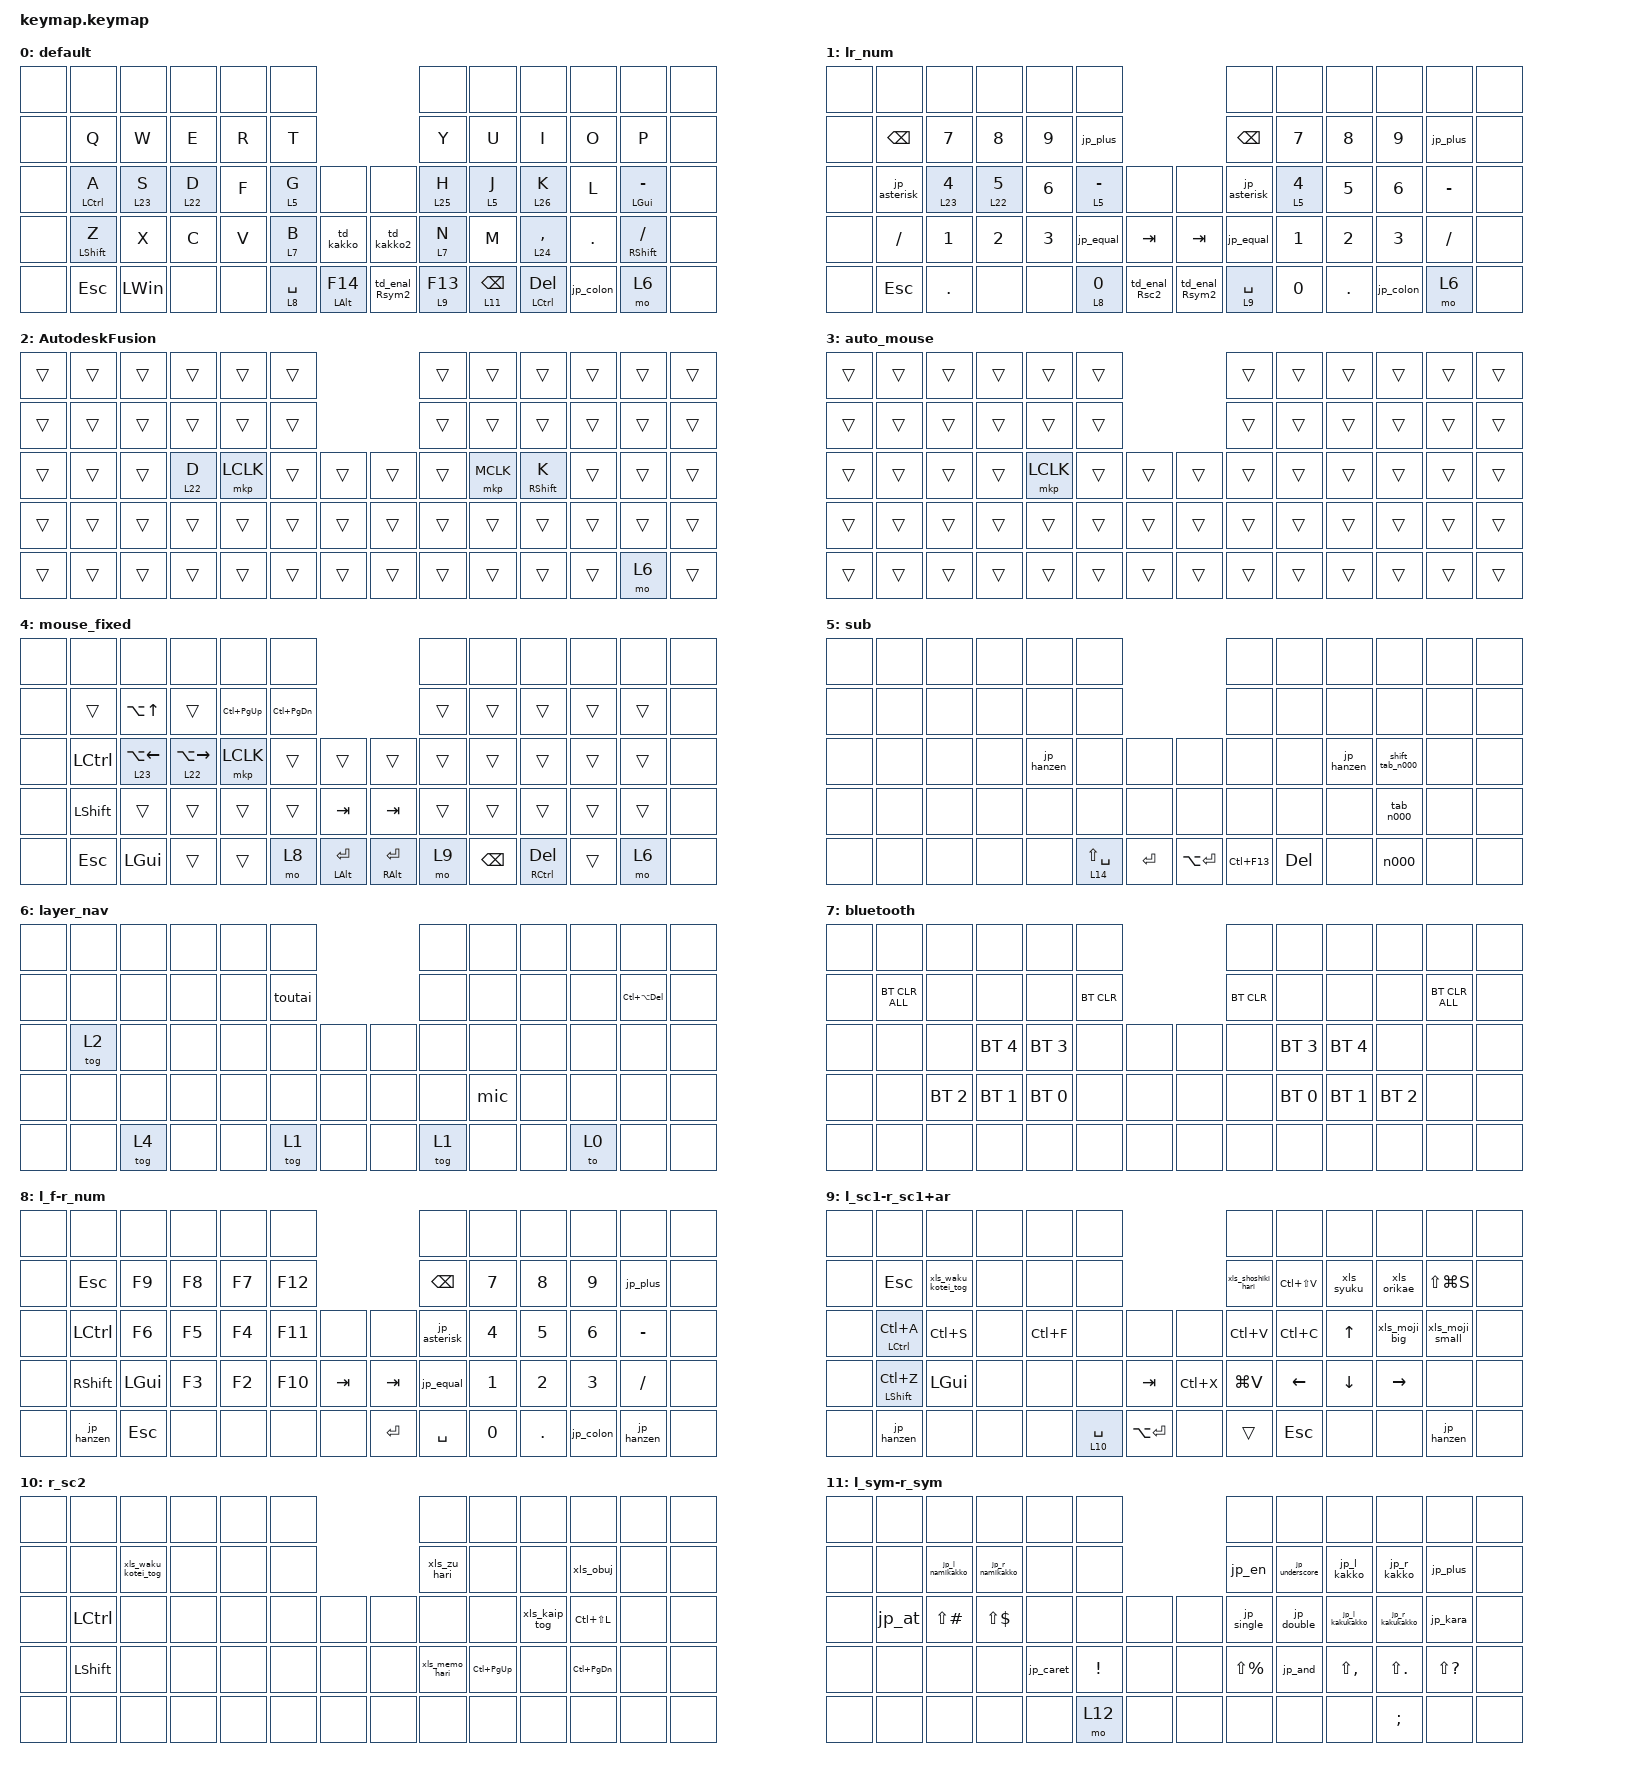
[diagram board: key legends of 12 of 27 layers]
/* 追記分（Input Processorsでレイヤー別動作やスクロール変換を使うため） */

#include <input/processors.dtsi>
#include <zephyr/dt-bindings/input/input-event-codes.h>
#include <dt-bindings/zmk/input_transform.h>
#include <dt-bindings/zmk/modifiers.h>
#include <behaviors.dtsi>
#include <dt-bindings/zmk/bt.h>
#include <dt-bindings/zmk/keys.h>
#include <dt-bindings/zmk/pointing.h>

/* HID usage(16進) をそのまま keycode 値として扱う（dtc が確実に数値として読める形） */

#define JP_KC_0x89  (0x89)  /* ¥ 系 */
#define JP_KC_0x87  (0x87)  /* _ 用 */

/* タップダンス用：行きたいレイヤー番号 */

#define LAYER_Rsc2 8
#define LAYER_LsRs 9
#define LAYER_Rsym2 10

/* ================== ここからDevicetreeオーバレイ本体 ================== */

/ {
    /* ===============================
     * トラックボール用 Input Processor 定義
     *  - my_vert_scroll   : Y → 縦スクロール
     *  - my_horiz_scroll  : X → 横スクロール
     *  - lock_cursor_x    : カーソルdXのみ 0倍（縦スクロール中に左右移動させない）
     *  - lock_cursor_y    : カーソルYのみ 0倍（横スクロール中に上下移動させない）
     * =============================== */

    input_processors {
        /* --- 縦スクロール専用 Code Mapper（Y → WHEEL） --- */

        my_vert_scroll: my_vert_scroll {
            compatible = "zmk,input-processor-code-mapper";
            #input-processor-cells = <0>;
            type = <INPUT_EV_REL>;
            map = <INPUT_REL_Y INPUT_REL_WHEEL>;
        };

        /* --- 横スクロール専用 Code Mapper（X → HWHEEL） --- */

        my_horiz_scroll: my_horiz_scroll {
            compatible = "zmk,input-processor-code-mapper";
            #input-processor-cells = <0>;
            type = <INPUT_EV_REL>;
            map = <INPUT_REL_X INPUT_REL_HWHEEL>;
        };

        /* --- カーソル X だけスケール 0倍にする（縦スクロール時に使用） --- */

        lock_cursor_x: lock_cursor_x {
            compatible = "zmk,input-processor-scaler";
            #input-processor-cells = <2>;   /* パラメータ 2つ（分子, 分母） */
            type = <INPUT_EV_REL>;

            /* X 方向の相対移動だけを対象 */

            codes = <INPUT_REL_X>;
            track-remainders;
        };

        /* --- カーソル Y だけスケール 0倍にする（横スクロール時に使用） --- */

        lock_cursor_y: lock_cursor_y {
            compatible = "zmk,input-processor-scaler";
            #input-processor-cells = <2>;   /* パラメータ 2つ（分子, 分母） */
            type = <INPUT_EV_REL>;

            /* Y 方向の相対移動だけを対象 */

            codes = <INPUT_REL_Y>;
            track-remainders;
        };

        /* しきい値・除外キーを調整したくなった時のためのテンプレ（現時点では未使用） */

        /omit-if-no-ref/

        my_temp_layer: my_temp_layer {
            compatible = "zmk,input-processor-temp-layer";
            #input-processor-cells = <2>;

            /* 例: ポインタ発動前に2秒間キータップが無ければ有効化したい場合に使う
             * require-prior-idle-ms = <2000>;
             * 無効化のきっかけにしないキー位置番号（必要になったら列挙）
             * excluded-positions = <10 11 12>;
             */
        };
    };

    /* --- コンボ定義（安全形に整形） --- */

    combos {
        compatible = "zmk,combos";

        combo_kakko {
            bindings = <&jp_lr_kakko>;
            key-positions = <21 20>;
            timeout-ms = <80>;
            layers = <11>;
        };

        combo_kakukakko {
            bindings = <&jp_lr_kakukakko>;
            key-positions = <34 35>;
            timeout-ms = <80>;
            layers = <11>;
        };

        combo_daisyou {
            bindings = <&jp_lr_dai_syou_nari>;
            key-positions = <48 49>;
            timeout-ms = <80>;
            layers = <11>;
        };

        combo_namikakko {
            bindings = <&jp_lr_namikakko>;
            key-positions = <14 15>;
            timeout-ms = <80>;
            layers = <11>;
        };

        combo_l_tab {
            bindings = <&kp TAB>;
            key-positions = <29 28>;
            timeout-ms = <80>;
        };

        combo_r_tab {
            bindings = <&kp TAB>;
            key-positions = <32 33>;
            timeout-ms = <80>;
        };

        combo_lshift {
            bindings = <&kp LSHIFT>;
            key-positions = <57 58>;
            timeout-ms = <80>;
            layers = <0>;
        };

        combo_rshift {
            bindings = <&kp RSHIFT>;
            key-positions = <59 60>;
            timeout-ms = <80>;
            layers = <0>;
        };

        combo_rclk {
            bindings = <&mkp LCLK>;
            key-positions = <33 34>;
            timeout-ms = <80>;
            slow-release;              /* ★重要：全キー離すまで保持 */
            layers = <3 4>;
        };

        combo_shift_rclk {
            bindings = <&mkp RCLK>;
            key-positions = <47 48>;
            timeout-ms = <80>;
            slow-release;              /* ★重要：全キー離すまで保持 */
            layers = <3 4>;
        };

        combo_shift_rclk3 {
            bindings = <&shift_rclk>;
            key-positions = <19 20>;
            timeout-ms = <80>;
            slow-release;
            layers = <3 4>;
        };

        combo_mclk {
            bindings = <&mkp MCLK>;
            key-positions = <34 35>;
            timeout-ms = <80>;
            slow-release;              /* ★重要：全キー離すまで保持 */
            layers = <3 4>;
        };

        combo_sh_mclk {
            bindings = <&sh_mclk_hold>;
            key-positions = <48 49>;   /* ←ここを自分のコンボ位置に */
            timeout-ms = <80>;         /* 打鍵が速いなら 60〜90 あたりで調整 */
            slow-release;              /* ★重要：全キー離すまで保持 */
            layers = <3 4>;
        };

        combo_rclk2 {
            bindings = <&mkp RCLK>;
            key-positions = <28 27>;
            timeout-ms = <80>;
            slow-release;
            layers = <3 4>;
        };

        combo_shift_rclk2 {
            bindings = <&shift_rclk>;
            key-positions = <42 41>;
            timeout-ms = <80>;
            slow-release;
            layers = <3 4>;
        };

        combo_mclk2 {
            bindings = <&mkp MCLK>;
            key-positions = <26 27>;
            timeout-ms = <80>;
            slow-release;
            layers = <3 4>;
        };

        combo_sh_mclk2 {
            bindings = <&sh_mclk_hold>;
            key-positions = <40 41>;
            timeout-ms = <80>;
            slow-release;
            layers = <3 4>;
        };

    };

    /* --- クイックタップ・タップダンスなど --- */

    behaviors {
        qt_lt: qt_layer_tap {
            compatible = "zmk,behavior-hold-tap";
            #binding-cells = <2>;
            flavor = "tap-preferred";
            tapping-term-ms = <250>;

            /* ★これが肝：タップ後すぐ再押下したら「必ずtap」扱いにする */

            quick-tap-ms = <200>;

            /* hold = &mo（レイヤー）、tap = &kp（キー） */

            bindings = <&mo>, <&kp>;
        };

        qt_mt: qt_modtap {
            compatible = "zmk,behavior-hold-tap";
            #binding-cells = <2>;
            flavor = "tap-preferred";
            tapping-term-ms = <250>;

            /* ★2回目（一定時間内の再押下）は必ず tap 扱いにする */

            quick-tap-ms = <200>;

            /* hold（前） と tap（後） の両方とも &kp を使う */

            bindings = <&kp>, <&kp>;
        };

        td_enal_Rsc2: td_enal_Rsc2 {
            compatible = "zmk,behavior-tap-dance";
            #binding-cells = <0>;
            tapping-term-ms = <250>;

            /* 1回目: &mt (tap=Enter, hold=Alt)
           2回目: &lt (tap=Enter, LAYER_Rsc2(8)) */

            bindings = <&mt LALT ENTER>, <&lt 10 ENTER>;
        };

        td_enal_Rsym2: td_enal_Rsym2 {
            compatible = "zmk,behavior-tap-dance";
            #binding-cells = <0>;
            tapping-term-ms = <250>;

            /* 1回目: &mt (tap=Enter, hold=Alt)
           2回目: &lt (tap=Enter, LAYER_Rsym2(10)) */

            bindings = <&mt LALT ENTER>, <&lt 12 ENTER>;
        };

        td_kakko: td_kakko {
            compatible = "zmk,behavior-tap-dance";
            #binding-cells = <0>;
            tapping-term-ms = <250>;

            /* 1 tap: &jp_l_kakko
           2 taps: &jp_l_kakukakko */

            bindings = <&jp_l_kakko>, <&jp_l_kakukakko>;
        };

        td_kakko2: td_kakko2 {
            compatible = "zmk,behavior-tap-dance";
            #binding-cells = <0>;
            tapping-term-ms = <250>;

            /* 1 tap: &jp_r_kakko
           2 taps: &jp_r_kakukakko */

            bindings = <&jp_r_kakko>, <&jp_r_kakukakko>;
        };
    };

    /* --- マクロ --- */

    macros {
        /* ========= シフト右クリック ========= */

        shift_rclk: shift_rclk {
            compatible = "zmk,behavior-macro";
            #binding-cells = <0>;

            /* 必要なら待ち時間を調整 */

            wait-ms = <10>;
            tap-ms = <20>;
            bindings =
                <&macro_press>,
                <&kp LSHIFT>,
                <&macro_tap>,
                <&mkp MB2>,
                <&macro_release>,
                <&kp LSHIFT>;
        };

        sh_mclk_hold: sh_mclk_hold {
            compatible = "zmk,behavior-macro";
            #binding-cells = <0>;

            /* 速く確実に：押下/解放を即時にしたいので 0 に寄せる */

            wait-ms = <0>;
            tap-ms = <0>;
            bindings =
                <&macro_press>,
                <&kp LSHFT>,
                <&macro_press>,
                <&mkp MCLK>,
                <&macro_pause_for_release>,
                <&macro_release>,
                <&mkp MCLK>,
                <&macro_release>,
                <&kp LSHFT>;
        };

        /* ========= JP(OS=日本語配列)向け 記号マクロ ここから========= */

        jp_double: jp_double {
            compatible = "zmk,behavior-macro";
            #binding-cells = <0>;
            bindings = <&macro_tap>, <&kp AT>;
        };

        jp_and: jp_and {
            compatible = "zmk,behavior-macro";
            #binding-cells = <0>;
            bindings = <&macro_tap>, <&kp CARET>;
        };

        jp_single: jp_single {
            compatible = "zmk,behavior-macro";
            #binding-cells = <0>;
            bindings = <&macro_tap>, <&kp AMPS>;
        };

        jp_equal: jp_equal {
            compatible = "zmk,behavior-macro";
            #binding-cells = <0>;
            bindings = <&macro_tap>, <&kp UNDER>;
        };

        jp_caret: jp_caret {
            compatible = "zmk,behavior-macro";
            #binding-cells = <0>;
            bindings = <&macro_tap>, <&kp EQUAL>;
        };

        jp_en: jp_en {
            compatible = "zmk,behavior-macro";
            #binding-cells = <0>;
            bindings = <&macro_tap>, <&kp JP_KC_0x89>;
        };

        jp_plus: jp_plus {
            compatible = "zmk,behavior-macro";
            #binding-cells = <0>;
            bindings = <&macro_tap>, <&kp COLON>;
        };

        jp_kara: jp_kara {
            compatible = "zmk,behavior-macro";
            #binding-cells = <0>;
            bindings = <&macro_tap>, <&kp PLUS>;
        };

        jp_pipe: jp_pipe {
            compatible = "zmk,behavior-macro";
            #binding-cells = <0>;
            bindings =
                <&macro_press>,
                <&kp LSHIFT>,
                <&macro_tap>,
                <&kp JP_KC_0x89>,
                <&macro_release>,
                <&kp LSHIFT>;
        };

        jp_at: jp_at {
            compatible = "zmk,behavior-macro";
            #binding-cells = <0>;
            bindings = <&macro_tap>, <&kp LBKT>;
        };

        jp_colon: jp_colon {
            compatible = "zmk,behavior-macro";
            #binding-cells = <0>;
            bindings = <&macro_tap>, <&kp SQT>;
        };

        jp_asterisk: jp_asterisk {
            compatible = "zmk,behavior-macro";
            #binding-cells = <0>;
            bindings = <&macro_tap>, <&kp DQT>;
        };

        jp_backquote: jp_backquote {
            compatible = "zmk,behavior-macro";
            #binding-cells = <0>;
            bindings = <&macro_tap>, <&kp LBRC>;
        };

        jp_underscore: jp_underscore {
            compatible = "zmk,behavior-macro";
            #binding-cells = <0>;
            bindings =
                <&macro_press>,
                <&kp LSHIFT>,
                <&macro_tap>,
                <&kp JP_KC_0x87>,
                <&macro_release>,
                <&kp LSHIFT>;
        };

        jp_l_kakukakko: jp_l_kakukakko {
            compatible = "zmk,behavior-macro";
            #binding-cells = <0>;
            bindings = <&macro_tap>, <&kp RBKT>;
        };

        jp_r_kakukakko: jp_r_kakukakko {
            compatible = "zmk,behavior-macro";
            #binding-cells = <0>;
            bindings = <&macro_tap>, <&kp BSLH>;
        };

        jp_lr_kakukakko: jp_lr_kakukakko {
            compatible = "zmk,behavior-macro";
            #binding-cells = <0>;
            bindings = <&macro_tap>, <&kp F2 &kp RBKT &kp BSLH &kp LEFT>;

            wait-ms = <20>;
            tap-ms = <20>;
        };

        jp_l_kakko: jp_l_kakko {
            compatible = "zmk,behavior-macro";
            #binding-cells = <0>;
            bindings = <&macro_tap>, <&kp STAR>;
        };

        jp_r_kakko: jp_r_kakko {
            compatible = "zmk,behavior-macro";
            #binding-cells = <0>;
            bindings = <&macro_tap>, <&kp LPAR>;
        };

        jp_lr_kakko: jp_lr_kakko {
            compatible = "zmk,behavior-macro";
            #binding-cells = <0>;
            bindings = <&macro_tap>, <&kp F2 &kp STAR &kp LPAR &kp LEFT>;

            wait-ms = <20>;
            tap-ms = <20>;
        };

        jp_l_namikakko: jp_l_namikakko {
            compatible = "zmk,behavior-macro";
            #binding-cells = <0>;
            bindings = <&macro_tap>, <&kp RBRC>;
        };

        jp_r_namikakko: jp_r_namikakko {
            compatible = "zmk,behavior-macro";
            #binding-cells = <0>;
            bindings =
                <&macro_press>,
                <&kp LSHIFT>,
                <&macro_tap>,
                <&kp BSLH>,
                <&macro_release>,
                <&kp LSHIFT>;
        };

        jp_lr_namikakko: jp_lr_namikakko {
            compatible = "zmk,behavior-macro";
            #binding-cells = <0>;
            bindings =
                <&macro_tap>,
                <&kp F2 &kp RBRC>,
                <&macro_press>,
                <&kp LSHIFT>,
                <&macro_tap>,
                <&kp BSLH>,
                <&macro_release>,
                <&kp LSHIFT>,
                <&macro_tap>,
                <&kp LEFT>;
        };

        jp_lr_dai_syou_nari: jp_lr_dai_syou_nari {
            compatible = "zmk,behavior-macro";
            #binding-cells = <0>;
            bindings =
                <&macro_tap>,
                <&kp F2 &kp LS(COMMA) &kp LS(PERIOD) &kp LEFT>;

            wait-ms = <20>;
            tap-ms = <20>;
        };

        jp_kana: jp_kana {
            compatible = "zmk,behavior-macro";
            #binding-cells = <0>;
            bindings = <&macro_tap>, <&kp LANG1>;
        };

        jp_eisu: jp_eisu {
            compatible = "zmk,behavior-macro";
            #binding-cells = <0>;
            bindings = <&macro_tap>, <&kp LANG2>;
        };

        jp_hanzen: jp_hanzen {
            compatible = "zmk,behavior-macro";
            #binding-cells = <0>;
            bindings = <&macro_tap>, <&kp GRAVE>;
        };

        /* ========= Excel向けマクロ ここから========= */

        xls_moji_big: xls_moji_big {
            compatible = "zmk,behavior-macro";
            #binding-cells = <0>;
            bindings = <&macro_tap>, <&kp LALT &kp H &kp F &kp G>;

            label = "MOJI_BIG";
            wait-ms = <10>;
            tap-ms = <10>;
        };

        xls_moji_small: xls_moji_small {
            compatible = "zmk,behavior-macro";
            #binding-cells = <0>;
            bindings = <&macro_tap>, <&kp LALT &kp H &kp F &kp K>;

            label = "MOJI_SMALL";
            wait-ms = <10>;
            tap-ms = <10>;
        };

        xls_syuku: xls_syukusyou {
            compatible = "zmk,behavior-macro";
            #binding-cells = <0>;
            bindings =
                <&macro_tap>,
                <&kp LALT &kp H &kp F &kp A &kp LA(K) &kp ENTER>;

            label = "SYUKUSYOU";
            wait-ms = <10>;
            tap-ms = <20>;
        };

        xls_orikae: xls_orikae {
            compatible = "zmk,behavior-macro";
            #binding-cells = <0>;
            bindings = <&macro_tap>, <&kp LALT &kp H &kp W>;

            label = "ORIKAE";
            wait-ms = <10>;
            tap-ms = <20>;
        };

        /* Ctrl+Alt+Shift+F：書式のみ貼り付け（Excel側の独自関数に割当済み想定）dddd */

        xls_shoshiki_hari: xls_shoshiki_hari {
            compatible = "zmk,behavior-macro";
            label = "XLS_SHOSHIKI_HARI";
            #binding-cells = <0>;
            wait-ms = <10>;
            tap-ms = <0>;
            bindings =
                <&macro_press>,
                <&kp LCTRL &kp LALT &kp LSHIFT>,
                <&macro_tap>,
                <&kp F>,
                <&macro_release>,
                <&kp LSHIFT &kp LALT &kp LCTRL>;
        };

        /* Ctrl+Alt+Shift+C：コメント・メモのみ貼り付け（Excel側の独自関数に割当済み想定） */

        xls_memo_hari: xls_memo_hari {
            compatible = "zmk,behavior-macro";
            label = "XLSs_MEMO_HARI";
            #binding-cells = <0>;
            wait-ms = <10>;
            tap-ms = <0>;
            bindings =
                <&macro_press>,
                <&kp LCTRL &kp LALT &kp LSHIFT>,
                <&macro_tap>,
                <&kp C>,
                <&macro_release>,
                <&kp LSHIFT &kp LALT &kp LCTRL>;
        };

        /* Ctrl+Alt+Shift+P：図として貼り付け（Excel側の独自関数に割当済み想定） */

        xls_zu_hari: xls_zu_hari {
            compatible = "zmk,behavior-macro";
            label = "XLS_ZU_HARI";
            #binding-cells = <0>;
            wait-ms = <10>;
            tap-ms = <0>;
            bindings =
                <&macro_press>,
                <&kp LCTRL &kp LALT &kp LSHIFT>,
                <&macro_tap>,
                <&kp P>,
                <&macro_release>,
                <&kp LSHIFT &kp LALT &kp LCTRL>;
        };

        /* オブジェクトの選択：Alt, H, F, D, O（Select Objects） */

        xls_obuj: xls_obuj {
            compatible = "zmk,behavior-macro";
            label = "xls_OBUJ";
            #binding-cells = <0>;
            wait-ms = <40>;
            tap-ms = <0>;
            bindings = <&macro_tap>, <&kp LALT &kp H &kp F &kp D &kp O>;
        };

        /* Ctrl+Alt+Shift+L：ウィンドウ枠固定トグル（Excel側の独自関数に割当済み想定） */

        xls_waku_kotei_tog: xls_waku_kotei_toggle {
            compatible = "zmk,behavior-macro";
            label = "XLS_WAKU_KOTEI_TOGGLE";
            #binding-cells = <0>;
            wait-ms = <10>;
            tap-ms = <0>;
            bindings =
                <&macro_press>,
                <&kp LCTRL &kp LALT &kp LSHIFT>,
                <&macro_tap>,
                <&kp L>,
                <&macro_release>,
                <&kp LSHIFT &kp LALT &kp LCTRL>;
        };

        /* Ctrl+Alt+Shift+B：改ページプレビュートグル（Excel側の独自関数に割当済み想定） */

        xls_kaip_tog: xls_kaip_toggle {
            compatible = "zmk,behavior-macro";
            label = "XLS_KAIP_TOGGLE";
            #binding-cells = <0>;
            wait-ms = <10>;
            tap-ms = <0>;
            bindings =
                <&macro_press>,
                <&kp LCTRL &kp LALT &kp LSHIFT>,
                <&macro_tap>,
                <&kp B>,
                <&macro_release>,
                <&kp LSHIFT &kp LALT &kp LCTRL>;
        };

        /* ========= 個別sys用マクロ ========= */

        toutai: toutai {
            compatible = "zmk,behavior-macro";
            #binding-cells = <0>;

            // 公式推奨に寄せて余裕を持たせる

            wait-ms = <20>;
            tap-ms = <20>;
            bindings =
                <&macro_tap>,
                <&kp U &kp N &kp I &kp D &kp E &kp F &kp N2 &kp C &kp H &kp I &kp B &kp A &kp JP_KC_0x89 &kp N0 &kp N1 &kp N1 &kp N0 &kp N5 &kp N1 &kp N0 &kp N4 &kp TAB &kp LS(C) &kp H &kp I &kp B &kp A &kp N0 &kp N1 &kp N1 &kp N0 &kp N5 &kp N1 &kp N0 &kp N4 &kp ENTER>;

            label = "TOUTAI";
        };

        mic: mic {
            compatible = "zmk,behavior-macro";
            #binding-cells = <0>;
            bindings = <&kp LS(K) &kp MINUS &kp A &kp R &kp I &kp T &kp A &kp N2 &kp N2 &kp N5 &kp M &kp ENTER>;
            label = "MIC";
            wait-ms = <10>;
            tap-ms = <10>;
        };

        sym_left: sym_left {
            compatible = "zmk,behavior-macro";
            #binding-cells = <0>;
            bindings = <&kp F13 &kp Y &kp M &kp F13 &kp ENTER>;
            wait-ms = <10>;
            tap-ms = <10>;
        };

        sym_up: sym_up {
            compatible = "zmk,behavior-macro";
            #binding-cells = <0>;
            bindings = <&kp F13 &kp Y &kp K &kp F13 &kp ENTER>;
            wait-ms = <10>;
            tap-ms = <10>;
        };

        sym_down: sym_down {
            compatible = "zmk,behavior-macro";
            #binding-cells = <0>;
            bindings = <&kp F13 &kp Y &kp COMMA &kp F13 &kp ENTER>;
            wait-ms = <10>;
            tap-ms = <10>;
        };

        sym_right: sym_rite {
            compatible = "zmk,behavior-macro";
            #binding-cells = <0>;
            bindings = <&kp F13 &kp Y &kp PERIOD &kp F13 &kp ENTER>;
            wait-ms = <10>;
            tap-ms = <10>;
        };

        /* ========= Shift+Tab×11, Space, Shift+Tab×6, Space, "n000" ========= */

        shift_tab_n000: shift_tab_n000 {
            compatible = "zmk,behavior-macro";
            #binding-cells = <0>;
            wait-ms = <30>;
            tap-ms = <20>;
            bindings =
                <&macro_press>,
                <&kp LSHIFT>,
                <&macro_tap>,
                <&kp TAB &kp TAB &kp TAB &kp TAB &kp TAB &kp TAB &kp TAB &kp TAB &kp TAB &kp TAB &kp TAB>,
                <&macro_release>,
                <&kp LSHIFT>,
                <&macro_tap>,
                <&kp SPACE>,
                <&macro_press>,
                <&kp LSHIFT>,
                <&macro_tap>,
                <&kp TAB &kp TAB &kp TAB &kp TAB &kp TAB &kp TAB>,
                <&macro_release>,
                <&kp LSHIFT>,
                <&macro_tap>,
                <&kp SPACE &kp N &kp N0 &kp N0 &kp N0>;
        };

        /* ========= Tab×9, "n000" ========= */

        tab_n000: tab_n000 {
            compatible = "zmk,behavior-macro";
            #binding-cells = <0>;
            wait-ms = <30>;
            tap-ms = <20>;
            bindings = <&kp TAB &kp TAB &kp TAB &kp TAB &kp TAB &kp TAB &kp TAB &kp TAB &kp TAB &kp N &kp N0 &kp N0 &kp N0>;
        };

        n000: n000 {
            compatible = "zmk,behavior-macro";
            #binding-cells = <0>;
            wait-ms = <10>;
            tap-ms = <10>;
            bindings = <&kp N &kp N0 &kp N0 &kp N0>;
        };

    };

    /* --- 単押・長押設定：グローバル hold-tap 設定 --- */

    behaviors {
        hold_tap {
            /* Mod-Tap / Layer-Tap (&mt / &lt) の共通設定 */

            tapping-term-ms = <250>;

            /* 必要に応じて追加
             * quick-tap-ms = <0>;
             * require-prior-idle-ms = <0>;
             * flavor = "hold-preferred";
             */
        };
    };

    /* --- キーマップ --- */

    keymap {
        compatible = "zmk,keymap";

        default {
            bindings = <
&none  &none             &none         &none     &none  &none                                             &none      &none           &none             &none      &none                 &none
&none  &kp Q             &kp W         &kp E     &kp R  &kp T                                             &kp Y      &kp U           &kp I             &kp O      &kp P                 &none
&none  &mt LCTRL A       &lt 23 S      &lt 22 D  &kp F  &lt 5 G         &none             &none           &lt 25 H   &lt 5 J         &lt 26 K          &kp L      &mt LGUI MINUS        &none
&none  &mt LEFT_SHIFT Z  &kp X         &kp C     &kp V  &lt 7 B         &td_kakko         &td_kakko2      &lt 7 N    &kp M           &lt 24 COMMA      &kp DOT    &mt RIGHT_SHIFT FSLH  &none
&none  &kp ESC           &kp LEFT_WIN  &none     &none  &qt_lt 8 SPACE  &mt LEFT_ALT F14  &td_enal_Rsym2  &lt 9 F13  &qt_lt 11 BSPC  &qt_mt LCTRL DEL  &jp_colon  &mo 6                 &none
            >;
        };

        lr_num {
            bindings = <
&none  &none         &none       &none      &none         &none                                       &none         &none     &none         &none      &none      &none
&none  &kp BSPC      &kp N7      &kp N8     &kp N9        &jp_plus                                    &kp BSPC      &kp N7    &kp N8        &kp N9     &jp_plus   &none
&none  &jp_asterisk  &lt 23 N4   &lt 22 N5  &kp NUMBER_6  &lt 5 MINUS  &none          &none           &jp_asterisk  &lt 5 N4  &kp N5        &kp N6     &kp MINUS  &none
&none  &kp SLASH     &kp N1      &kp N2     &kp N3        &jp_equal    &kp TAB        &kp TAB         &jp_equal     &kp N1    &kp NUMBER_2  &kp N3     &kp SLASH  &none
&none  &kp ESC       &kp PERIOD  &none      &none         &lt 8 N0     &td_enal_Rsc2  &td_enal_Rsym2  &lt 9 SPACE   &kp N0    &kp PERIOD    &jp_colon  &mo 6      &none
            >;
        };

        AutodeskFusion {
            bindings = <
&trans  &trans  &trans  &trans    &trans     &trans                  &trans  &trans     &trans             &trans  &trans  &trans
&trans  &trans  &trans  &trans    &trans     &trans                  &trans  &trans     &trans             &trans  &trans  &trans
&trans  &trans  &trans  &lt 22 D  &mkp LCLK  &trans  &trans  &trans  &trans  &mkp MCLK  &mt RIGHT_SHIFT K  &trans  &trans  &trans
&trans  &trans  &trans  &trans    &trans     &trans  &trans  &trans  &trans  &trans     &trans             &trans  &trans  &trans
&trans  &trans  &trans  &trans    &trans     &trans  &trans  &trans  &trans  &trans     &trans             &trans  &mo 6   &trans
            >;
        };

        auto_mouse {
            bindings = <
&trans  &trans  &trans  &trans  &trans     &trans                  &trans  &trans     &trans  &trans  &trans  &trans
&trans  &trans  &trans  &trans  &trans     &trans                  &trans  &trans     &trans  &trans  &trans  &trans
&trans  &trans  &trans  &trans  &mkp LCLK  &trans  &trans  &trans  &trans  &trans     &trans  &trans  &trans  &trans
&trans  &trans  &trans  &trans  &trans     &trans  &trans  &trans  &trans  &trans     &trans  &trans  &trans  &trans
&trans  &trans  &trans  &trans  &trans     &trans  &trans  &trans  &trans  &trans     &trans  &trans  &trans  &trans
            >;
        };

        mouse_fixed {
            bindings = <
&none  &none      &none            &none             &none          &none                                          &none   &none          &none          &none   &none   &none
&none  &trans     &kp LA(UP)       &trans            &kp LC(PG_UP)  &kp LC(PG_DN)                                  &trans  &trans         &trans         &trans  &trans  &none
&none  &kp LCTRL  &lt 23 LA(LEFT)  &lt 22 LA(RIGHT)  &mkp LCLK      &trans         &trans          &trans          &trans  &trans         &trans         &trans  &trans  &none
&none  &kp LSHFT  &trans           &trans            &trans         &trans         &kp TAB         &kp TAB         &trans  &trans         &trans         &trans  &trans  &none
&none  &kp ESC    &kp LGUI         &trans            &trans         &mo 8          &mt LALT ENTER  &mt RALT ENTER  &mo 9   &kp BACKSPACE  &mt RCTRL DEL  &trans  &mo 6   &none
            >;
        };

        sub {
            bindings = <
&none  &none  &none  &none            &none       &none                                       &none        &none    &none       &none  &none  &none
&none  &none  &none  &none            &none       &none                                        &none        &none    &none       &none  &none  &none
&none  &none  &none  &none            &jp_hanzen  &none             &none      &none          &none        &none    &jp_hanzen  &shift_tab_n000  &none  &none
&none  &none  &none  &none            &none       &none             &none      &none          &none        &none    &none       &tab_n000  &none  &none
&none  &none  &none  &none            &none       &lt 14 LS(SPACE)  &kp ENTER  &kp LA(ENTER)  &kp LC(F13)  &kp DEL  &none       &n000  &none  &none
            >;
        };

        layer_nav {
            bindings = <
&none  &none   &none   &none  &none  &none                  &none   &none  &none  &none  &none            &none
&none  &none   &none   &none  &none  &toutai                &none   &none  &none  &none  &kp LC(LA(DEL))  &none
&none  &tog 2  &none   &none  &none  &none    &none  &none  &none   &none  &none  &none  &none            &none
&none  &none   &none   &none  &none  &none    &none  &none  &none   &mic   &none  &none  &none            &none
&none  &none   &tog 4  &none  &none  &tog 1   &none  &none  &tog 1  &none  &none  &to 0  &none            &none
            >;
        };

        bluetooth {
            bindings = <
&none  &none           &none         &none         &none         &none                     &none       &none         &none         &none         &none           &none
&none  &bt BT_CLR_ALL  &none         &none         &none         &bt BT_CLR                &bt BT_CLR  &none         &none         &none         &bt BT_CLR_ALL  &none
&none  &none           &none         &bt BT_SEL 4  &bt BT_SEL 3  &none       &none  &none  &none       &bt BT_SEL 3  &bt BT_SEL 4  &none         &none           &none
&none  &none           &bt BT_SEL 2  &bt BT_SEL 1  &bt BT_SEL 0  &none       &none  &none  &none       &bt BT_SEL 0  &bt BT_SEL 1  &bt BT_SEL 2  &none           &none
&none  &none           &none         &none         &none         &none       &none  &none  &none       &none         &none         &none         &none           &none
            >;
        };

        l_f-r_num {
            bindings = <
&none  &none       &none         &none   &none   &none                      &none         &none   &none    &none      &none       &none
&none  &kp ESC     &kp F9        &kp F8  &kp F7  &kp F12                    &kp BSPC      &kp N7  &kp N8   &kp N9     &jp_plus    &none
&none  &kp LCTRL   &kp F6        &kp F5  &kp F4  &kp F11  &none    &none    &jp_asterisk  &kp N4  &kp N5   &kp N6     &kp MINUS   &none
&none  &kp RSHFT   &kp LEFT_GUI  &kp F3  &kp F2  &kp F10  &kp TAB  &kp TAB  &jp_equal     &kp N1  &kp N2   &kp N3     &kp FSLH    &none
&none  &jp_hanzen  &kp ESC       &none   &none   &none    &none    &kp RET  &kp SPACE     &kp N0  &kp DOT  &jp_colon  &jp_hanzen  &none
            >;
        };

        l_sc1-r_sc1+ar {
            bindings = <
&none  &none            &none                &none  &none      &none                                    &none               &none          &none       &none          &none            &none
&none  &kp ESC          &xls_waku_kotei_tog  &none  &none      &none                                    &xls_shoshiki_hari  &kp LC(LS(V))  &xls_syuku  &xls_orikae    &kp LS(LG(S))    &none
&none  &mt LCTRL LC(A)  &kp LC(S)            &none  &kp LC(F)  &none            &none        &none      &kp LC(V)           &kp LC(C)      &kp UP      &xls_moji_big  &xls_moji_small  &none
&none  &mt LSHFT LC(Z)  &kp LEFT_GUI         &none  &none      &none            &kp TAB      &kp LC(X)  &kp LG(V)           &kp LEFT       &kp DOWN    &kp RIGHT      &none            &none
&none  &jp_hanzen       &none                &none  &none      &qt_lt 10 SPACE  &kp LA(RET)  &none      &trans              &kp ESC        &none       &none          &jp_hanzen       &none
            >;
        };

        r_sc2 {
            bindings = <
&none  &none      &none                &none  &none  &none                &none           &none          &none          &none              &none  &none
&none  &none      &xls_waku_kotei_tog  &none  &none  &none                &xls_zu_hari    &none          &none          &xls_obuj          &none  &none
&none  &kp LCTRL  &none                &none  &none  &none  &none  &none  &none           &none          &xls_kaip_tog  &kp LC(LS(L))      &none  &none
&none  &kp LSHFT  &none                &none  &none  &none  &none  &none  &xls_memo_hari  &kp LC(PG_UP)  &none          &kp LC(PAGE_DOWN)  &none  &none
&none  &none      &none                &none  &none  &none  &none  &none  &none           &none          &none          &none              &none  &none
            >;
        };

        l_sym-r_sym {
            bindings = <
&none  &none   &none            &none            &none      &none                          &none          &none           &none            &none            &none          &none
&none  &none   &jp_l_namikakko  &jp_r_namikakko  &none      &none                          &jp_en         &jp_underscore  &jp_l_kakko      &jp_r_kakko      &jp_plus       &none
&none  &jp_at  &kp LS(POUND)    &kp LS(DLLR)     &none      &none            &none  &none  &jp_single     &jp_double      &jp_l_kakukakko  &jp_r_kakukakko  &jp_kara       &none
&none  &none   &none            &none            &jp_caret  &kp EXCLAMATION  &none  &none  &kp LS(PRCNT)  &jp_and         &kp LS(COMMA)    &kp LS(PERIOD)   &kp LS(QMARK)  &none
&none  &none   &none            &none            &none      &mo 12           &none  &none  &none          &none           &none            &kp SEMICOLON    &none          &none
            >;
        };

        r_sym2 {
            bindings = <
&trans  &trans  &trans  &trans  &trans  &trans                  &trans  &trans     &trans     &trans      &trans  &trans
&trans  &trans  &trans  &trans  &trans  &trans                  &trans  &trans     &trans     &trans      &trans  &trans
&trans  &trans  &trans  &trans  &trans  &trans  &trans  &trans  &trans  &trans     &sym_up    &trans      &trans  &trans
&trans  &trans  &trans  &trans  &trans  &trans  &trans  &trans  &trans  &sym_left  &sym_down  &sym_right  &trans  &trans
&trans  &trans  &trans  &trans  &trans  &trans  &trans  &trans  &trans  &trans     &trans     &trans      &trans  &trans
            >;
        };

        micjet_default {
            bindings = <
&trans  &trans  &trans   &trans  &trans  &trans                       &trans     &trans    &trans     &trans     &trans     &trans
&trans  &kp Q   &kp W    &kp E   &kp R   &kp T                        &kp Y      &kp U     &kp I      &kp O      &kp P      &trans
&trans  &kp A   &kp S    &kp D   &kp F   &kp G      &trans   &trans   &kp H      &kp J     &kp K      &kp L      &kp MINUS  &trans
&trans  &kp Z   &kp X    &kp C   &kp V   &kp B      &kp TAB  &kp TAB  &kp N      &kp M     &kp COMMA  &kp DOT    &kp FSLH   &trans
&trans  &trans  &kp ESC  &trans  &trans  &kp SPACE  &kp RET  &kp RET  &kp SPACE  &kp BSPC  &kp DEL    &kp COLON  &mo 6      &trans
            >;
        };

        r_num_hankaku {
            bindings = <
&none  &none  &none  &none  &none  &none                    &none            &none      &none       &none      &none         &none
&none  &none  &none  &none  &none  &none                    &kp BSPC         &kp KP_N7  &kp KP_N8   &kp KP_N9  &kp KP_PLUS   &none
&none  &none  &none  &none  &none  &none  &none  &none      &kp KP_ASTERISK  &kp KP_N4  &kp KP_N5   &kp KP_N6  &kp KP_MINUS  &none
&none  &none  &none  &none  &none  &none  &none  &kp TAB    &kp KP_EQUAL     &kp KP_N1  &kp KP_N2   &kp KP_N3  &kp KP_SLASH  &none
&none  &none  &none  &none  &none  &none  &none  &kp ENTER  &lt 9 F13        &kp KP_N0  &kp PERIOD  &jp_colon  &none         &none
            >;
        };

        layer_13 {
            bindings = <
&trans  &trans  &trans  &trans  &trans  &trans                  &trans  &trans  &trans  &trans  &trans  &trans
&trans  &trans  &trans  &trans  &trans  &trans                  &trans  &trans  &trans  &trans  &trans  &trans
&trans  &trans  &trans  &trans  &trans  &trans  &trans  &trans  &trans  &trans  &trans  &trans  &trans  &trans
&trans  &trans  &trans  &trans  &trans  &trans  &trans  &trans  &trans  &trans  &trans  &trans  &trans  &trans
&trans  &trans  &trans  &trans  &trans  &trans  &trans  &trans  &trans  &trans  &trans  &trans  &trans  &trans
            >;
        };

        layer_14 {
            bindings = <
&trans  &trans  &trans  &trans  &trans  &trans                  &trans  &trans  &trans  &trans  &trans  &trans
&trans  &trans  &trans  &trans  &trans  &trans                  &trans  &trans  &trans  &trans  &trans  &trans
&trans  &trans  &trans  &trans  &trans  &trans  &trans  &trans  &trans  &trans  &trans  &trans  &trans  &trans
&trans  &trans  &trans  &trans  &trans  &trans  &trans  &trans  &trans  &trans  &trans  &trans  &trans  &trans
&trans  &trans  &trans  &trans  &trans  &trans  &trans  &trans  &trans  &trans  &trans  &trans  &trans  &trans
            >;
        };

        layer_15 {
            bindings = <
&trans  &trans  &trans  &trans  &trans  &trans                  &trans  &trans  &trans  &trans  &trans  &trans
&trans  &trans  &trans  &trans  &trans  &trans                  &trans  &trans  &trans  &trans  &trans  &trans
&trans  &trans  &trans  &trans  &trans  &trans  &trans  &trans  &trans  &trans  &trans  &trans  &trans  &trans
&trans  &trans  &trans  &trans  &trans  &trans  &trans  &trans  &trans  &trans  &trans  &trans  &trans  &trans
&trans  &trans  &trans  &trans  &trans  &trans  &trans  &trans  &trans  &trans  &trans  &trans  &trans  &trans
            >;
        };

        layer_16 {
            bindings = <
&trans  &trans  &trans  &trans  &trans  &trans                  &trans  &trans  &trans  &trans  &trans  &trans
&trans  &trans  &trans  &trans  &trans  &trans                  &trans  &trans  &trans  &trans  &trans  &trans
&trans  &trans  &trans  &trans  &trans  &trans  &trans  &trans  &trans  &trans  &trans  &trans  &trans  &trans
&trans  &trans  &trans  &trans  &trans  &trans  &trans  &trans  &trans  &trans  &trans  &trans  &trans  &trans
&trans  &trans  &trans  &trans  &trans  &trans  &trans  &trans  &trans  &trans  &trans  &trans  &trans  &trans
            >;
        };

        layer_17 {
            bindings = <
&trans  &trans  &trans  &trans  &trans  &trans                  &trans  &trans  &trans  &trans  &trans  &trans
&trans  &trans  &trans  &trans  &trans  &trans                  &trans  &trans  &trans  &trans  &trans  &trans
&trans  &trans  &trans  &trans  &trans  &trans  &trans  &trans  &trans  &trans  &trans  &trans  &trans  &trans
&trans  &trans  &trans  &trans  &trans  &trans  &trans  &trans  &trans  &trans  &trans  &trans  &trans  &trans
&trans  &trans  &trans  &trans  &trans  &trans  &trans  &trans  &trans  &trans  &trans  &trans  &trans  &trans
            >;
        };

        layer_18 {
            bindings = <
&trans  &trans  &trans  &trans  &trans  &trans                  &trans  &trans  &trans  &trans  &trans  &trans
&trans  &trans  &trans  &trans  &trans  &trans                  &trans  &trans  &trans  &trans  &trans  &trans
&trans  &trans  &trans  &trans  &trans  &trans  &trans  &trans  &trans  &trans  &trans  &trans  &trans  &trans
&trans  &trans  &trans  &trans  &trans  &trans  &trans  &trans  &trans  &trans  &trans  &trans  &trans  &trans
&trans  &trans  &trans  &trans  &trans  &trans  &trans  &trans  &trans  &trans  &trans  &trans  &trans  &trans
            >;
        };

        layer_19 {
            bindings = <
&trans  &trans  &trans  &trans  &trans  &trans                  &trans  &trans  &trans  &trans  &trans  &trans
&trans  &trans  &trans  &trans  &trans  &trans                  &trans  &trans  &trans  &trans  &trans  &trans
&trans  &trans  &trans  &trans  &trans  &trans  &trans  &trans  &trans  &trans  &trans  &trans  &trans  &trans
&trans  &trans  &trans  &trans  &trans  &trans  &trans  &trans  &trans  &trans  &trans  &trans  &trans  &trans
&trans  &trans  &trans  &trans  &trans  &trans  &trans  &trans  &trans  &trans  &trans  &trans  &trans  &trans
            >;
        };

        scroll_v_tate {
            bindings = <
&none  &none  &none          &none  &none  &none                &none  &none  &none  &none  &none  &none
&none  &none  &none          &none  &none  &none                &none  &none  &none  &none  &none  &none
&none  &none  &kp LS(LCTRL)  &none  &none  &none  &none  &none  &none  &none  &none  &none  &none  &none
&none  &none  &none          &none  &none  &none  &none  &none  &none  &none  &none  &none  &none  &none
&none  &none  &none          &none  &none  &none  &none  &none  &none  &none  &none  &none  &none  &none
            >;
        };

        scroll_h_yoko {
            bindings = <
&none  &none  &none  &none  &none  &none                &none  &none  &none  &none  &none  &none
&none  &none  &none  &none  &none  &none                &none  &none  &none  &none  &none  &none
&none  &none  &none  &none  &none  &none  &none  &none  &none  &none  &none  &none  &none  &none
&none  &none  &none  &none  &none  &none  &none  &none  &none  &none  &none  &none  &none  &none
&none  &none  &none  &none  &none  &none  &none  &none  &none  &none  &none  &none  &none  &none
            >;
        };

        scroll_xy {
            bindings = <
&trans  &trans  &trans  &trans  &trans  &trans                  &trans  &trans  &trans  &trans  &trans  &trans
&trans  &trans  &trans  &trans  &trans  &trans                  &trans  &trans  &trans  &trans  &trans  &trans
&trans  &trans  &trans  &trans  &trans  &trans  &trans  &trans  &trans  &trans  &trans  &trans  &trans  &trans
&trans  &trans  &trans  &trans  &trans  &trans  &trans  &trans  &trans  &trans  &trans  &trans  &trans  &trans
&trans  &trans  &trans  &trans  &trans  &trans  &trans  &trans  &trans  &trans  &trans  &trans  &trans  &trans
            >;
        };

        cursor_slow {
            bindings = <
&trans  &trans  &trans  &trans  &trans  &trans                  &trans  &trans  &trans  &trans  &trans  &trans
&trans  &trans  &trans  &trans  &trans  &trans                  &trans  &trans  &trans  &trans  &trans  &trans
&trans  &trans  &trans  &trans  &trans  &trans  &trans  &trans  &trans  &trans  &trans  &trans  &trans  &trans
&trans  &trans  &trans  &trans  &trans  &trans  &trans  &trans  &trans  &trans  &trans  &trans  &trans  &trans
&trans  &trans  &trans  &trans  &trans  &trans  &trans  &trans  &trans  &trans  &trans  &trans  &trans  &trans
            >;
        };

        scrl_fast {
            bindings = <
&trans  &trans  &trans  &trans  &trans  &trans                  &trans  &trans  &trans  &trans  &trans  &trans
&trans  &trans  &trans  &trans  &trans  &trans                  &trans  &trans  &trans  &trans  &trans  &trans
&trans  &trans  &trans  &trans  &trans  &trans  &trans  &trans  &trans  &trans  &trans  &trans  &trans  &trans
&trans  &trans  &trans  &trans  &trans  &trans  &trans  &trans  &trans  &trans  &trans  &trans  &trans  &trans
&trans  &trans  &trans  &trans  &trans  &trans  &trans  &trans  &trans  &trans  &trans  &trans  &trans  &trans
            >;
        };
    };
}; /* ===== / ここまで ===== */
/* === トラックボール入力リスナーへの割当（trackball_listener） === */
/*
 * NOTE: torabo-tsuki LP トラックボール設定について
 *  - &trackball_listener をここで再定義しているため、
 *    boards/shields/... や snippets/... にある同名 listener の
 *    input-processors 設定は上書きされます。
 *  - トラックボールの向き・スクロール・速度などは
 *    すべてこの keymap.keymap で調整する方針とする。
 */

&trackball_listener {
    /* ★向き補正（公式相当）＋ポインタ入力時に自動マウスLayer3 を一時有効にする */

    input-processors = <
        &zip_xy_transform (INPUT_TRANSFORM_X_INVERT | INPUT_TRANSFORM_Y_INVERT)
        &zip_xy_scaler 6 5
        &my_temp_layer 3 800
    >;

    /* --------------------------------------
     * Layer22: 縦スクロール（Y → Wheel）
     *   - my_vert_scroll : Y をスクロールに変換
     *   - lock_cursor_x  : X を 0倍にしてカーソルの左右移動を殺す
     * -------------------------------------- */

    scroll_v {
        layers = <22>;
        input-processors = <
            &my_vert_scroll         /* Y → WHEEL */
            &lock_cursor_x 0 1      /* X 移動を 0倍（カーソル左右ロック） */
            &zip_scroll_scaler 1 12  /* スクロール速度1/12 */
        >;

        process-next;
    };

    /* --------------------------------------
     * Layer23: 横スクロール（X → HWheel, 向き反転）
     *   - my_horiz_scroll : X を横スクロールに変換
     *   - zip_scroll_transform : 横スクロールの向きを反転
     *   - lock_cursor_y   : Y を 0倍にしてカーソルの上下移動を殺す
     * -------------------------------------- */

    scroll_h {
        layers = <23>;
        input-processors = <
            &my_horiz_scroll                        /* X → HWHEEL */
            &zip_scroll_transform INPUT_TRANSFORM_X_INVERT  /* 横スクロール方向反転 */
            &lock_cursor_y 0 1                      /* Y 移動を 0倍（カーソル上下ロック） */
            &zip_scroll_scaler 1 24                 /* スクロール速度1/24 */
        >;

        process-next;
    };

    /* --------------------------------------
     * Layer24: 縦＋横スクロール併用レイヤー
     *   - my_vert_scroll : Y を縦スクロールに変換
     *   - my_horiz_scroll: X を横スクロールに変換
     *   - lock_cursor_x  : 残った X 相対移動を 0 にして、左右へのカーソル移動を殺す
     *   - lock_cursor_y  : 残った Y 相対移動を 0 にして、上下へのカーソル移動を殺す
     * -------------------------------------- */

    scroll_both {
        layers = <24>;
        input-processors = <
            &my_vert_scroll         /* Y → WHEEL（縦スクロール） */
            &my_horiz_scroll        /* X → HWHEEL（横スクロール） */
            &zip_scroll_transform INPUT_TRANSFORM_X_INVERT  /* 横スクロール方向反転 */
            &lock_cursor_x 0 1      /* X の相対移動を 0倍（カーソル左右ロック） */
            &lock_cursor_y 0 1      /* Y の相対移動を 0倍（カーソル上下ロック） */
            &zip_scroll_scaler 1 24  /* スクロール速度1/24 */
        >;

        process-next;
    };

    /* 速度プリセット: Layer25 = カーソル低速 */

    speed_slow {
        layers = <25>;
        input-processors = <&zip_xy_scaler 1 4>;
        process-next;
    };

    /* 速度プリセット: Layer26 = スクロール高速 */

    scrl_fast {
        layers = <26>;
        input-processors = <&zip_scroll_scaler 24 1>;
        process-next;
    };
};

/* 既存の &mt (mod-tap) の設定を上書き */

&mt {
    tapping-term-ms = <250>;     /* 例：200→250ms に短縮 */
    flavor = "balanced";         /* 好みで */
    /* quick-tap-ms = <150>; */  /* 必要なときだけ（デフォは無効） */
    /* require-prior-idle-ms = <125>; */ /* 高速入力時はTap固定にしたいなら */
};
